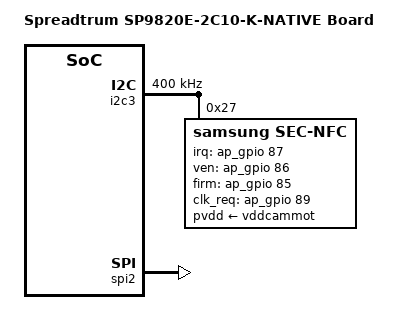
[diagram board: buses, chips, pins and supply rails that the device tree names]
/*
 * Spreadtrum sharkle sp9820e KaiOS board DTS file
 *
 * Copyright (C) 2017, Spreadtrum Communications Inc.
 *
 * This file is licensed under a dual GPLv2 or X11 license.
 */

#include "sp9820e-2c10-native.dts"

/ {
	model = "Spreadtrum SP9820E-2C10-K-NATIVE Board";

	reserved-memory {
		tos_reserved: tos-mem@8e100000{
			reg = <0x8e100000 0x00500000>;
		};

		/* 400k for tui before fb_reserved */
		tui_reserved: tui_mem@8fada000{
			reg = <0x8fada000 0x00064000>;
		};
	};
};

&i2c3 {
	status = "okay";
	clock-frequency = <400000>;

	sec-nfc@27 {
		compatible = "samsung,sec-nfc";
		reg = <0x27>;
		clock-names = "clk_26m","source","enable";
		clocks = <&clk_aux0>,<&ext_26m>,
			 <&clk_aon_apb_gates1 2>;
		sec-nfc,irq-gpio = <&ap_gpio 87 0>;
		sec-nfc,ven-gpio = <&ap_gpio 86 0>;
		sec-nfc,firm-gpio = <&ap_gpio 85 0>;
		sec-nfc,clk_req-gpio = <&ap_gpio 89 0>;
		pvdd-supply = <&vddcammot>;
	};
};

/* use 192m for se */
&spi2 {
	clocks = <&clk_ap_apb_gates 7>,<&clk_spi2>,<&clk_twpll_192m>;
	status = "okay";
};

